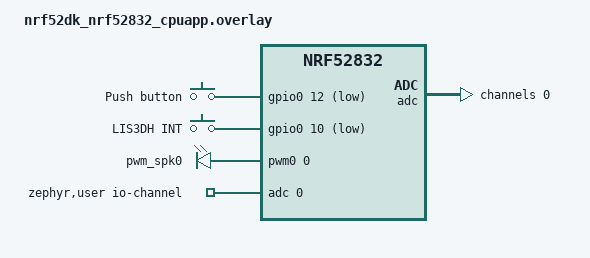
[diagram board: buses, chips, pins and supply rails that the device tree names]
/*
 * Copyright (c) 2024 Nordic Semiconductor ASA
 *
 * SPDX-License-Identifier: LicenseRef-Nordic-5-Clause
 */

 #include "nrf52dk_nrf52832_cpuapp_common.dtsi"

 / {
	/* These aliases are provided for compatibility with samples */
	aliases {
		pwm-spk = &pwm_spk0;
	};

	/*leds {
		compatible = "gpio-leds";
		led0: led_0 {
			gpios = <&gpio0 2 GPIO_ACTIVE_LOW>;
			label = "Red LED";
		};

		led1: led_1 {
			gpios = <&gpio0 3 GPIO_ACTIVE_LOW>;
			label = "Thermister Control";
		};
	};*/

	buttons {
		compatible = "gpio-keys";

		button0: button_0 {
			gpios = <&gpio0 12 (GPIO_PULL_UP | GPIO_ACTIVE_LOW)>;
			label = "Push button";
			zephyr,code = <INPUT_KEY_1>;
		};

		button1: button_1 {
			gpios = <&gpio0 10 (GPIO_PULL_UP | GPIO_ACTIVE_LOW)>;
			label = "LIS3DH INT";
			zephyr,code = <INPUT_KEY_2>;
		};

		/*button3: button_3 {
			gpios = <&gpio0 11 GPIO_ACTIVE_LOW>;
			label = "Door Sensor";
			zephyr,code = <INPUT_KEY_2>;
		};

		button2: button_2 {
			gpios = <&gpio0 12 GPIO_ACTIVE_LOW>;
			label = "Light Sensor";
			zephyr,code = <INPUT_KEY_3>;
		};*/
	};

	pwmspk {
		compatible = "pwm-leds";
		pwm_spk0: pwm-spk-0 {
			pwms = <&pwm0 0 PWM_MSEC(20) PWM_POLARITY_NORMAL>;
		};
	};

	zephyr,user {
		io-channels = <&adc 0>;
	};
};

&adc {
	#address-cells = <1>;
	#size-cells = <0>;
	status = "okay";
	channel@0 {
		reg = <0>;
		zephyr,gain = "ADC_GAIN_1_6";
		zephyr,reference = "ADC_REF_INTERNAL";
		zephyr,acquisition-time = <ADC_ACQ_TIME_DEFAULT>;
		zephyr,input-positive = <NRF_SAADC_VDD>; 
		zephyr,resolution = <10>;
	};

	/*channel@1 {
		reg = <1>;
		zephyr,gain = "ADC_GAIN_1_6";
		zephyr,reference = "ADC_REF_INTERNAL";
		zephyr,acquisition-time = <ADC_ACQ_TIME_DEFAULT>;
		zephyr,input-positive = <NRF_SAADC_AIN0>; 
		zephyr,resolution = <10>;
	};*/
};

/*&flash0 {
	partitions {
		compatible = "fixed-partitions";
		#address-cells = <1>;
		#size-cells = <1>;

		appconfig_storage_partition: partition@7e000 {
            label = "appconfig_storage";
            reg = <0x0007e000 0x00002000>;
        };
	};
};*/

&led1 {
    status = "disabled";
};

&led2 {
    status = "disabled";
};

&led3 {
    status = "disabled";
};

&button2 {
    status = "disabled";
};

&button3 {
    status = "disabled";
};

&i2c1
{
	status = "disabled";
};

&spi0 {
	status = "disabled";
};

&spi1 {
	status = "disabled";
};

&spi2 {
	status = "disabled";
};

/*
&button1 {
    status = "disabled";
};

&i2c0 {
    status = "disabled";
};

&pwm0 {
    status = "disabled";
};

&adc {
    status = "disabled";
};

&uart0 {
    status = "disabled";
};
*/
